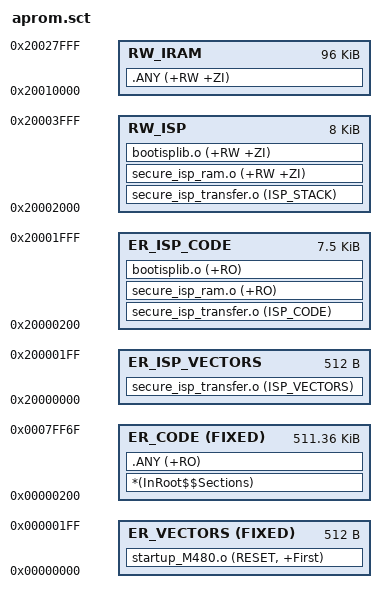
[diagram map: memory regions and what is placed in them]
; APROM holds the application and the load image copied to SRAM by the C runtime.
; The final 144 bytes are reserved for the APROM Secure Boot information block.
LR_APROM 0x00000000 0x0007FF70
{
    ER_VECTORS 0x00000000 FIXED 0x00000200
    {
        startup_M480.o (RESET, +First)
    }
    ER_CODE 0x00000200 FIXED 0x0007FD70
    {
        *(InRoot$$Sections)
        .ANY (+RO)
    }
    ER_ISP_VECTORS 0x20000000 0x00000200
    {
        secure_isp_transfer.o (ISP_VECTORS)
    }
    ER_ISP_CODE 0x20000200 0x00001E00
    {
        secure_isp_transfer.o (ISP_CODE)
        secure_isp_ram.o (+RO)
        bootisplib.o (+RO)
    }
    RW_ISP 0x20002000 0x00002000
    {
        secure_isp_transfer.o (ISP_STACK)
        secure_isp_ram.o (+RW +ZI)
        bootisplib.o (+RW +ZI)
    }
    ; Application RAM is separate from both the updater and the ROM work area.
    RW_IRAM 0x20010000 0x00018000
    {
        .ANY (+RW +ZI)
    }
}
